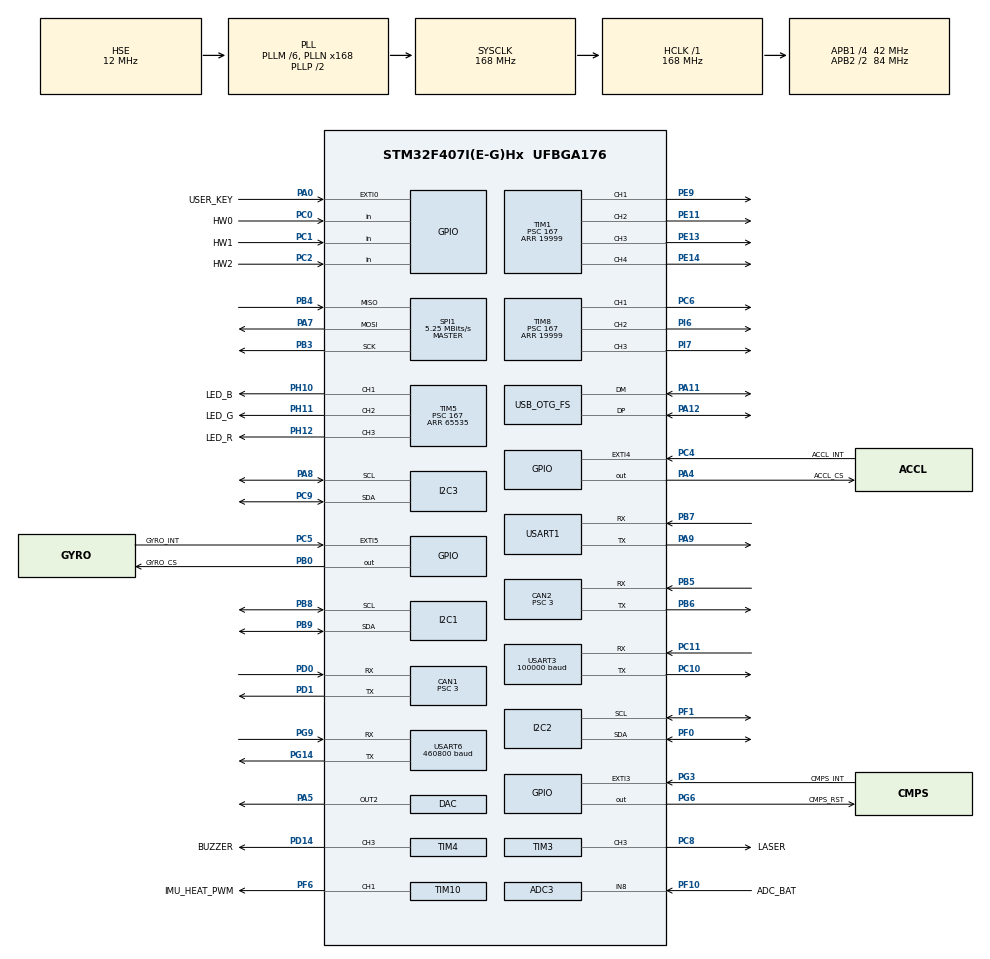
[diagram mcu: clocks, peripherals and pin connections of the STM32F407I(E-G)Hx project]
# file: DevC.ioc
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ADC1.Channel-0\#ChannelRegularConversion=ADC_CHANNEL_TEMPSENSOR
ADC1.Channel-1\#ChannelRegularConversion=ADC_CHANNEL_VREFINT
ADC1.ClockPrescaler=ADC_CLOCK_SYNC_PCLK_DIV6
ADC1.ContinuousConvMode=ENABLE
ADC1.DMAContinuousRequests=ENABLE
ADC1.NbrOfConversion=2
ADC1.NbrOfConversionFlag=1
ADC1.Rank-0\#ChannelRegularConversion=1
ADC1.Rank-1\#ChannelRegularConversion=2
ADC1.SamplingTime-0\#ChannelRegularConversion=ADC_SAMPLETIME_3CYCLES
ADC1.SamplingTime-1\#ChannelRegularConversion=ADC_SAMPLETIME_3CYCLES
ADC1.master=1
ADC3.Channel-0\#ChannelRegularConversion=ADC_CHANNEL_8
ADC3.ClockPrescaler=ADC_CLOCK_SYNC_PCLK_DIV6
ADC3.ContinuousConvMode=ENABLE
ADC3.DMAContinuousRequests=ENABLE
ADC3.NbrOfConversionFlag=1
ADC3.Rank-0\#ChannelRegularConversion=1
ADC3.SamplingTime-0\#ChannelRegularConversion=ADC_SAMPLETIME_3CYCLES
CAN1.ABOM=ENABLE
CAN1.AWUM=ENABLE
CAN1.BS1=CAN_BS1_6TQ
CAN1.BS2=CAN_BS2_7TQ
CAN1.CalculateBaudRate=1000000
CAN1.CalculateTimeBit=1000
CAN1.CalculateTimeQuantum=71.42857142857143
CAN1.Mode=CAN_MODE_NORMAL
CAN1.NART=ENABLE
CAN1.Prescaler=3
CAN1.TXFP=DISABLE
CAN2.ABOM=ENABLE
CAN2.AWUM=ENABLE
CAN2.BS1=CAN_BS1_6TQ
CAN2.BS2=CAN_BS2_7TQ
CAN2.CalculateBaudRate=1000000
CAN2.CalculateTimeBit=1000
CAN2.CalculateTimeQuantum=71.42857142857143
CAN2.Mode=CAN_MODE_NORMAL
CAN2.NART=ENABLE
CAN2.Prescaler=3
CAN2.TXFP=DISABLE
Dma.ADC1.11.Direction=DMA_PERIPH_TO_MEMORY
Dma.ADC1.11.FIFOMode=DMA_FIFOMODE_DISABLE
Dma.ADC1.11.Instance=DMA2_Stream4
Dma.ADC1.11.MemDataAlignment=DMA_MDATAALIGN_HALFWORD
Dma.ADC1.11.MemInc=DMA_MINC_ENABLE
Dma.ADC1.11.Mode=DMA_CIRCULAR
Dma.ADC1.11.PeriphDataAlignment=DMA_PDATAALIGN_HALFWORD
Dma.ADC1.11.PeriphInc=DMA_PINC_DISABLE
Dma.ADC1.11.Priority=DMA_PRIORITY_LOW
Dma.ADC3.10.Direction=DMA_PERIPH_TO_MEMORY
Dma.ADC3.10.FIFOMode=DMA_FIFOMODE_DISABLE
Dma.ADC3.10.Instance=DMA2_Stream1
Dma.ADC3.10.MemDataAlignment=DMA_MDATAALIGN_HALFWORD
Dma.ADC3.10.MemInc=DMA_MINC_ENABLE
Dma.ADC3.10.Mode=DMA_CIRCULAR
Dma.ADC3.10.PeriphDataAlignment=DMA_PDATAALIGN_HALFWORD
Dma.ADC3.10.PeriphInc=DMA_PINC_DISABLE
Dma.ADC3.10.Priority=DMA_PRIORITY_LOW
Dma.I2C2_TX.2.Direction=DMA_MEMORY_TO_PERIPH
Dma.I2C2_TX.2.FIFOMode=DMA_FIFOMODE_DISABLE
Dma.I2C2_TX.2.Instance=DMA1_Stream7
Dma.I2C2_TX.2.MemDataAlignment=DMA_MDATAALIGN_BYTE
Dma.I2C2_TX.2.MemInc=DMA_MINC_ENABLE
Dma.I2C2_TX.2.Mode=DMA_NORMAL
Dma.I2C2_TX.2.PeriphDataAlignment=DMA_PDATAALIGN_BYTE
Dma.I2C2_TX.2.PeriphInc=DMA_PINC_DISABLE
Dma.I2C2_TX.2.Priority=DMA_PRIORITY_HIGH
Dma.I2C3_RX.7.Direction=DMA_PERIPH_TO_MEMORY
Dma.I2C3_RX.7.FIFOMode=DMA_FIFOMODE_DISABLE
Dma.I2C3_RX.7.Instance=DMA1_Stream2
Dma.I2C3_RX.7.MemDataAlignment=DMA_MDATAALIGN_BYTE
Dma.I2C3_RX.7.MemInc=DMA_MINC_ENABLE
Dma.I2C3_RX.7.Mode=DMA_NORMAL
Dma.I2C3_RX.7.PeriphDataAlignment=DMA_PDATAALIGN_BYTE
Dma.I2C3_RX.7.PeriphInc=DMA_PINC_DISABLE
Dma.I2C3_RX.7.Priority=DMA_PRIORITY_LOW
Dma.I2C3_TX.9.Direction=DMA_MEMORY_TO_PERIPH
Dma.I2C3_TX.9.FIFOMode=DMA_FIFOMODE_DISABLE
Dma.I2C3_TX.9.Instance=DMA1_Stream4
Dma.I2C3_TX.9.MemDataAlignment=DMA_MDATAALIGN_BYTE
Dma.I2C3_TX.9.MemInc=DMA_MINC_ENABLE
Dma.I2C3_TX.9.Mode=DMA_NORMAL
Dma.I2C3_TX.9.PeriphDataAlignment=DMA_PDATAALIGN_BYTE
Dma.I2C3_TX.9.PeriphInc=DMA_PINC_DISABLE
Dma.I2C3_TX.9.Priority=DMA_PRIORITY_LOW
Dma.Request0=SPI1_RX
Dma.Request1=SPI1_TX
Dma.Request10=ADC3
Dma.Request11=ADC1
Dma.Request2=I2C2_TX
Dma.Request3=USART3_RX
Dma.Request4=USART6_RX
Dma.Request5=USART6_TX
Dma.Request6=USART1_TX
Dma.Request7=I2C3_RX
Dma.Request8=USART1_RX
Dma.Request9=I2C3_TX
Dma.SPI1_RX.0.Direction=DMA_PERIPH_TO_MEMORY
Dma.SPI1_RX.0.FIFOMode=DMA_FIFOMODE_DISABLE
Dma.SPI1_RX.0.Instance=DMA2_Stream0
Dma.SPI1_RX.0.MemDataAlignment=DMA_MDATAALIGN_BYTE
Dma.SPI1_RX.0.MemInc=DMA_MINC_ENABLE
Dma.SPI1_RX.0.Mode=DMA_NORMAL
Dma.SPI1_RX.0.PeriphDataAlignment=DMA_PDATAALIGN_BYTE
Dma.SPI1_RX.0.PeriphInc=DMA_PINC_DISABLE
Dma.SPI1_RX.0.Priority=DMA_PRIORITY_VERY_HIGH
Dma.SPI1_TX.1.Direction=DMA_MEMORY_TO_PERIPH
Dma.SPI1_TX.1.FIFOMode=DMA_FIFOMODE_DISABLE
Dma.SPI1_TX.1.Instance=DMA2_Stream3
Dma.SPI1_TX.1.MemDataAlignment=DMA_MDATAALIGN_BYTE
Dma.SPI1_TX.1.MemInc=DMA_MINC_ENABLE
Dma.SPI1_TX.1.Mode=DMA_NORMAL
Dma.SPI1_TX.1.PeriphDataAlignment=DMA_PDATAALIGN_BYTE
Dma.SPI1_TX.1.PeriphInc=DMA_PINC_DISABLE
Dma.SPI1_TX.1.Priority=DMA_PRIORITY_HIGH
Dma.USART1_RX.8.Direction=DMA_PERIPH_TO_MEMORY
Dma.USART1_RX.8.FIFOMode=DMA_FIFOMODE_DISABLE
Dma.USART1_RX.8.Instance=DMA2_Stream5
Dma.USART1_RX.8.MemDataAlignment=DMA_MDATAALIGN_BYTE
Dma.USART1_RX.8.MemInc=DMA_MINC_ENABLE
Dma.USART1_RX.8.Mode=DMA_NORMAL
Dma.USART1_RX.8.PeriphDataAlignment=DMA_PDATAALIGN_BYTE
Dma.USART1_RX.8.PeriphInc=DMA_PINC_DISABLE
Dma.USART1_RX.8.Priority=DMA_PRIORITY_MEDIUM
Dma.USART1_TX.6.Direction=DMA_MEMORY_TO_PERIPH
Dma.USART1_TX.6.FIFOMode=DMA_FIFOMODE_DISABLE
Dma.USART1_TX.6.Instance=DMA2_Stream7
Dma.USART1_TX.6.MemDataAlignment=DMA_MDATAALIGN_BYTE
Dma.USART1_TX.6.MemInc=DMA_MINC_ENABLE
Dma.USART1_TX.6.Mode=DMA_NORMAL
Dma.USART1_TX.6.PeriphDataAlignment=DMA_PDATAALIGN_BYTE
Dma.USART1_TX.6.PeriphInc=DMA_PINC_DISABLE
Dma.USART1_TX.6.Priority=DMA_PRIORITY_MEDIUM
Dma.USART3_RX.3.Direction=DMA_PERIPH_TO_MEMORY
Dma.USART3_RX.3.FIFOMode=DMA_FIFOMODE_DISABLE
Dma.USART3_RX.3.Instance=DMA1_Stream1
Dma.USART3_RX.3.MemDataAlignment=DMA_MDATAALIGN_BYTE
Dma.USART3_RX.3.MemInc=DMA_MINC_ENABLE
Dma.USART3_RX.3.Mode=DMA_NORMAL
Dma.USART3_RX.3.PeriphDataAlignment=DMA_PDATAALIGN_BYTE
Dma.USART3_RX.3.PeriphInc=DMA_PINC_DISABLE
Dma.USART3_RX.3.Priority=DMA_PRIORITY_HIGH
Dma.USART6_RX.4.Direction=DMA_PERIPH_TO_MEMORY
Dma.USART6_RX.4.FIFOMode=DMA_FIFOMODE_DISABLE
Dma.USART6_RX.4.Instance=DMA2_Stream2
Dma.USART6_RX.4.MemDataAlignment=DMA_MDATAALIGN_BYTE
Dma.USART6_RX.4.MemInc=DMA_MINC_ENABLE
Dma.USART6_RX.4.Mode=DMA_NORMAL
Dma.USART6_RX.4.PeriphDataAlignment=DMA_PDATAALIGN_BYTE
Dma.USART6_RX.4.PeriphInc=DMA_PINC_DISABLE
Dma.USART6_RX.4.Priority=DMA_PRIORITY_MEDIUM
Dma.USART6_TX.5.Direction=DMA_MEMORY_TO_PERIPH
Dma.USART6_TX.5.FIFOMode=DMA_FIFOMODE_DISABLE
Dma.USART6_TX.5.Instance=DMA2_Stream6
Dma.USART6_TX.5.MemDataAlignment=DMA_MDATAALIGN_BYTE
Dma.USART6_TX.5.MemInc=DMA_MINC_ENABLE
Dma.USART6_TX.5.Mode=DMA_NORMAL
Dma.USART6_TX.5.PeriphDataAlignment=DMA_PDATAALIGN_BYTE
Dma.USART6_TX.5.PeriphInc=DMA_PINC_DISABLE
Dma.USART6_TX.5.Priority=DMA_PRIORITY_MEDIUM
FREERTOS.INCLUDE_uxTaskPriorityGet=0
FREERTOS.INCLUDE_vTaskDelayUntil=1
FREERTOS.INCLUDE_vTaskDelete=0
FREERTOS.INCLUDE_vTaskPrioritySet=0
FREERTOS.INCLUDE_vTaskSuspend=0
FREERTOS.MEMORY_ALLOCATION=0
FREERTOS.Tasks01=defaultTask,0,4096,StartDefaultTask,Default,NULL,Dynamic,NULL,NULL
FREERTOS.configENABLE_BACKWARD_COMPATIBILITY=0
FREERTOS.configENABLE_FPU=1
FREERTOS.configGENERATE_RUN_TIME_STATS=1
FREERTOS.configMAX_PRIORITIES=6
FREERTOS.configTOTAL_HEAP_SIZE=1024*64
FREERTOS.configUSE_COUNTING_SEMAPHORES=1
FREERTOS.configUSE_MUTEXES=1
FREERTOS.configUSE_NEWLIB_REENTRANT=0
FREERTOS.configUSE_STATS_FORMATTING_FUNCTIONS=1
FREERTOS.configUSE_TRACE_FACILITY=1
I2C1.I2C_Mode=I2C_Fast
I2C2.I2C_Mode=I2C_Fast
I2C3.I2C_Mode=I2C_Fast
Mcu.Family=STM32F4
Mcu.Name=STM32F407I(E-G)Hx
Mcu.Package=UFBGA176
NVIC.CAN1_RX0_IRQn=true\:5\:0\:true\:false\:true\:true\:true\:true\:true
NVIC.CAN1_RX1_IRQn=true\:5\:0\:true\:false\:true\:true\:true\:true\:true
NVIC.CAN1_TX_IRQn=true\:5\:0\:true\:false\:true\:true\:true\:true\:true
NVIC.CAN2_RX0_IRQn=true\:5\:0\:true\:false\:true\:true\:true\:true\:true
NVIC.CAN2_RX1_IRQn=true\:5\:0\:true\:false\:true\:true\:true\:true\:true
NVIC.CAN2_TX_IRQn=true\:5\:0\:true\:false\:true\:true\:true\:true\:true
NVIC.DMA1_Stream1_IRQn=true\:5\:0\:true\:false\:true\:true\:false\:true\:true
NVIC.DMA1_Stream2_IRQn=true\:5\:0\:true\:false\:true\:true\:false\:true\:true
NVIC.DMA1_Stream4_IRQn=true\:5\:0\:false\:false\:true\:true\:false\:true\:true
NVIC.DMA1_Stream7_IRQn=true\:5\:0\:true\:false\:true\:true\:false\:true\:true
NVIC.DMA2_Stream0_IRQn=true\:5\:0\:true\:false\:true\:true\:false\:true\:true
NVIC.DMA2_Stream1_IRQn=true\:5\:0\:false\:false\:true\:true\:false\:true\:true
NVIC.DMA2_Stream2_IRQn=true\:5\:0\:true\:false\:true\:true\:false\:true\:true
NVIC.DMA2_Stream3_IRQn=true\:5\:0\:true\:false\:true\:true\:false\:true\:true
NVIC.DMA2_Stream4_IRQn=true\:5\:0\:false\:false\:true\:true\:false\:true\:true
NVIC.DMA2_Stream5_IRQn=true\:5\:0\:true\:false\:true\:true\:false\:true\:true
NVIC.DMA2_Stream6_IRQn=true\:5\:0\:true\:false\:true\:true\:false\:true\:true
NVIC.DMA2_Stream7_IRQn=true\:5\:0\:true\:false\:true\:true\:false\:true\:true
NVIC.EXTI0_IRQn=true\:5\:0\:true\:false\:true\:true\:true\:true\:true
NVIC.EXTI3_IRQn=true\:5\:0\:true\:false\:true\:true\:true\:true\:true
NVIC.EXTI4_IRQn=true\:5\:0\:true\:false\:true\:true\:true\:true\:true
NVIC.EXTI9_5_IRQn=true\:5\:0\:true\:false\:true\:true\:true\:true\:true
NVIC.I2C3_EV_IRQn=true\:5\:0\:false\:false\:true\:true\:true\:true\:true
NVIC.OTG_FS_IRQn=true\:5\:0\:true\:false\:true\:true\:true\:true\:true
NVIC.PriorityGroup=NVIC_PRIORITYGROUP_4
NVIC.SPI1_IRQn=true\:5\:0\:false\:false\:true\:true\:true\:true\:true
NVIC.TIM1_BRK_TIM9_IRQn=true\:5\:0\:true\:false\:true\:true\:false\:true\:true
NVIC.TIM2_IRQn=true\:15\:0\:true\:false\:true\:false\:false\:true\:true
NVIC.TIM7_IRQn=true\:5\:0\:true\:false\:true\:true\:true\:true\:true
NVIC.TimeBase=TIM2_IRQn
NVIC.TimeBaseIP=TIM2
NVIC.USART1_IRQn=true\:5\:0\:true\:false\:true\:true\:true\:true\:true
NVIC.USART3_IRQn=true\:5\:0\:false\:false\:true\:true\:true\:true\:true
NVIC.USART6_IRQn=true\:5\:0\:true\:false\:true\:true\:true\:true\:true
PA0-WKUP.GPIO_Label=USER_KEY
PA0-WKUP.GPIO_ModeDefaultEXTI=GPIO_MODE_IT_FALLING
PA0-WKUP.GPIO_PuPd=GPIO_PULLUP
PA0-WKUP.Signal=GPXTI0
PA11.Mode=Device_Only
PA11.Signal=USB_OTG_FS_DM
PA12.Mode=Device_Only
PA12.Signal=USB_OTG_FS_DP
PA13.Mode=Serial_Wire
PA13.Signal=SYS_JTMS-SWDIO
PA14.Mode=Serial_Wire
PA14.Signal=SYS_JTCK-SWCLK
PA4.GPIO_Label=ACCL_CS
PA4.GPIO_PuPd=GPIO_PULLUP
PA4.GPIO_Speed=GPIO_SPEED_FREQ_MEDIUM
PA4.PinState=GPIO_PIN_SET
PA4.Signal=GPIO_Output
PA5.Signal=COMP_DAC2_group
PA7.GPIO_PuPd=GPIO_PULLUP
PA7.Mode=Full_Duplex_Master
PA7.Signal=SPI1_MOSI
PA8.GPIO_Pu=GPIO_PULLUP
PA8.Mode=I2C
PA8.Signal=I2C3_SCL
PA9.Mode=Asynchronous
PA9.Signal=USART1_TX
PB0.GPIO_Label=GYRO_CS
PB0.GPIO_PuPd=GPIO_PULLUP
PB0.GPIO_Speed=GPIO_SPEED_FREQ_MEDIUM
PB0.PinState=GPIO_PIN_SET
PB0.Signal=GPIO_Output
PB14.GPIO_PuPd=GPIO_PULLUP
PB14.Signal=SPI2_MISO
PB15.GPIO_PuPd=GPIO_PULLUP
PB15.Signal=SPI2_MOSI
PB3.GPIO_PuPd=GPIO_PULLUP
PB3.Mode=Full_Duplex_Master
PB3.Signal=SPI1_SCK
PB4.GPIO_PuPd=GPIO_PULLUP
PB4.Mode=Full_Duplex_Master
PB4.Signal=SPI1_MISO
PB5.Mode=CAN_Activate
PB5.Signal=CAN2_RX
PB6.Mode=CAN_Activate
PB6.Signal=CAN2_TX
PB7.Mode=Asynchronous
PB7.Signal=USART1_RX
PB8.GPIO_Pu=GPIO_PULLUP
PB8.Mode=I2C
PB8.Signal=I2C1_SCL
PB9.GPIO_Pu=GPIO_PULLUP
PB9.Mode=I2C
PB9.Signal=I2C1_SDA
PC0.GPIO_Label=HW0
PC0.Signal=GPIO_Input
PC1.GPIO_Label=HW1
PC1.Signal=GPIO_Input
PC10.Mode=Asynchronous
PC10.Signal=USART3_TX
PC11.Mode=Asynchronous
PC11.Signal=USART3_RX
PC2.GPIO_Label=HW2
PC2.Signal=GPIO_Input
PC4.GPIO_Label=ACCL_INT
PC4.GPIO_ModeDefaultEXTI=GPIO_MODE_IT_FALLING
PC4.GPIO_PuPd=GPIO_PULLUP
PC4.Signal=GPXTI4
PC5.GPIO_Label=GYRO_INT
PC5.GPIO_ModeDefaultEXTI=GPIO_MODE_IT_FALLING
PC5.GPIO_PuPd=GPIO_PULLUP
PC5.Signal=GPXTI5
PC6.GPIO_PuPd=GPIO_PULLUP
PC6.GPIO_Speed=GPIO_SPEED_FREQ_HIGH
PC6.Signal=S_TIM8_CH1
PC8.GPIO_Label=LASER
PC8.GPIO_PuPd=GPIO_PULLUP
PC8.GPIO_Speed=GPIO_SPEED_FREQ_HIGH
PC8.Signal=S_TIM3_CH3
PC9.GPIO_Pu=GPIO_PULLUP
PC9.Mode=I2C
PC9.Signal=I2C3_SDA
PD0.Mode=CAN_Activate
PD0.Signal=CAN1_RX
PD1.Mode=CAN_Activate
PD1.Signal=CAN1_TX
PD14.GPIO_Label=BUZZER
PD14.GPIO_PuPd=GPIO_PULLUP
PD14.GPIO_Speed=GPIO_SPEED_FREQ_VERY_HIGH
PD14.Signal=S_TIM4_CH3
PE11.GPIO_PuPd=GPIO_PULLUP
PE11.GPIO_Speed=GPIO_SPEED_FREQ_HIGH
PE11.Signal=S_TIM1_CH2
PE13.GPIO_PuPd=GPIO_PULLUP
PE13.GPIO_Speed=GPIO_SPEED_FREQ_HIGH
PE13.Signal=S_TIM1_CH3
PE14.GPIO_PuPd=GPIO_PULLUP
PE14.GPIO_Speed=GPIO_SPEED_FREQ_HIGH
PE14.Signal=S_TIM1_CH4
PE9.GPIO_PuPd=GPIO_PULLUP
PE9.GPIO_Speed=GPIO_SPEED_FREQ_HIGH
PE9.Signal=S_TIM1_CH1
PF0.GPIO_Pu=GPIO_PULLUP
PF0.Mode=I2C
PF0.Signal=I2C2_SDA
PF1.GPIO_Pu=GPIO_PULLUP
PF1.Mode=I2C
PF1.Signal=I2C2_SCL
PF10.GPIO_Label=ADC_BAT
PF10.Mode=IN8
PF10.Signal=ADC3_IN8
PF6.GPIO_Label=IMU_HEAT_PWM
PF6.GPIO_PuPd=GPIO_PULLDOWN
PF6.GPIO_Speed=GPIO_SPEED_FREQ_HIGH
PF6.Signal=S_TIM10_CH1
PG14.Mode=Asynchronous
PG14.Signal=USART6_TX
PG3.GPIO_Label=CMPS_INT
PG3.GPIO_ModeDefaultEXTI=GPIO_MODE_IT_FALLING
PG3.GPIO_PuPd=GPIO_PULLUP
PG3.Signal=GPXTI3
PG6.GPIO_Label=CMPS_RST
PG6.GPIO_PuPd=GPIO_PULLUP
PG6.GPIO_Speed=GPIO_SPEED_FREQ_MEDIUM
PG6.PinState=GPIO_PIN_RESET
PG6.Signal=GPIO_Output
PG9.Mode=Asynchronous
PG9.Signal=USART6_RX
PH0-OSC_IN.Mode=HSE-External-Oscillator
PH0-OSC_IN.Signal=RCC_OSC_IN
PH1-OSC_OUT.Mode=HSE-External-Oscillator
PH1-OSC_OUT.Signal=RCC_OSC_OUT
PH10.GPIO_Label=LED_B
PH10.GPIO_PuPd=GPIO_PULLUP
PH10.GPIO_Speed=GPIO_SPEED_FREQ_HIGH
PH10.Signal=S_TIM5_CH1
PH11.GPIO_Label=LED_G
PH11.GPIO_PuPd=GPIO_PULLUP
PH11.GPIO_Speed=GPIO_SPEED_FREQ_HIGH
PH11.Signal=S_TIM5_CH2
PH12.GPIO_Label=LED_R
PH12.GPIO_PuPd=GPIO_PULLUP
PH12.GPIO_Speed=GPIO_SPEED_FREQ_HIGH
PH12.Signal=S_TIM5_CH3
PI6.GPIO_PuPd=GPIO_PULLUP
PI6.GPIO_Speed=GPIO_SPEED_FREQ_HIGH
PI6.Signal=S_TIM8_CH2
PI7.Signal=S_TIM8_CH3
ProjectManager.HeapSize=0x1000
ProjectManager.StackSize=0x1000
ProjectManager.TargetToolchain=CMake
RCC.48MHZClocksFreq_Value=48000000
RCC.AHBFreq_Value=168000000
RCC.APB1CLKDivider=RCC_HCLK_DIV4
RCC.APB1Freq_Value=42000000
RCC.APB1TimFreq_Value=84000000
RCC.APB2CLKDivider=RCC_HCLK_DIV2
RCC.APB2Freq_Value=84000000
RCC.APB2TimFreq_Value=168000000
RCC.CortexFreq_Value=168000000
RCC.HCLKFreq_Value=168000000
RCC.HSE_VALUE=12000000
RCC.HSI_VALUE=16000000
RCC.LSE_VALUE=32768
RCC.PLLM=6
RCC.PLLN=168
RCC.PLLQ=7
RCC.RCC_RTC_Clock_Source=RCC_RTCCLKSOURCE_LSI
RCC.RCC_RTC_Clock_SourceVirtual=RCC_RTCCLKSOURCE_HSE_DIV30
RCC.RCC_RTC_Clock_Source_FROM_HSE=RCC_RTCCLKSOURCE_HSE_DIV30
RCC.SYSCLKFreq_VALUE=168000000
RCC.SYSCLKSource=RCC_SYSCLKSOURCE_PLLCLK
RCC.VCOOutputFreq_Value=336000000
SH.COMP_DAC2_group.0=DAC_OUT2,DAC_OUT2
SH.S_TIM10_CH1.0=TIM10_CH1,PWM Generation1 CH1
SH.S_TIM1_CH1.0=TIM1_CH1,PWM Generation1 CH1
SH.S_TIM1_CH2.0=TIM1_CH2,PWM Generation2 CH2
SH.S_TIM1_CH3.0=TIM1_CH3,PWM Generation3 CH3
SH.S_TIM1_CH4.0=TIM1_CH4,PWM Generation4 CH4
SH.S_TIM3_CH3.0=TIM3_CH3,PWM Generation3 CH3
SH.S_TIM4_CH3.0=TIM4_CH3,PWM Generation3 CH3
SH.S_TIM5_CH1.0=TIM5_CH1,PWM Generation1 CH1
SH.S_TIM5_CH2.0=TIM5_CH2,PWM Generation2 CH2
SH.S_TIM5_CH3.0=TIM5_CH3,PWM Generation3 CH3
SH.S_TIM8_CH1.0=TIM8_CH1,PWM Generation1 CH1
SH.S_TIM8_CH2.0=TIM8_CH2,PWM Generation2 CH2
SH.S_TIM8_CH3.0=TIM8_CH3,PWM Generation3 CH3
SPI1.BaudRatePrescaler=SPI_BAUDRATEPRESCALER_16
SPI1.CLKPhase=SPI_PHASE_2EDGE
SPI1.CLKPolarity=SPI_POLARITY_HIGH
SPI1.CalculateBaudRate=5.25 MBits/s
SPI1.Direction=SPI_DIRECTION_2LINES
SPI1.Mode=SPI_MODE_MASTER
SPI1.VirtualType=VM_MASTER
TIM1.Channel-PWM\ Generation1\ CH1=TIM_CHANNEL_1
TIM1.Channel-PWM\ Generation2\ CH2=TIM_CHANNEL_2
TIM1.Channel-PWM\ Generation3\ CH3=TIM_CHANNEL_3
TIM1.Channel-PWM\ Generation4\ CH4=TIM_CHANNEL_4
TIM1.Period=19999
TIM1.Prescaler=167
TIM1.Pulse-PWM\ Generation1\ CH1=0
TIM1.Pulse-PWM\ Generation2\ CH2=0
TIM1.Pulse-PWM\ Generation3\ CH3=0
TIM1.Pulse-PWM\ Generation4\ CH4=1000
TIM10.Channel=TIM_CHANNEL_1
TIM10.Period=4999
TIM10.Prescaler=167
TIM3.Channel-PWM\ Generation3\ CH3=TIM_CHANNEL_3
TIM3.Period=65535
TIM3.Prescaler=167
TIM4.Channel-PWM\ Generation3\ CH3=TIM_CHANNEL_3
TIM4.Period=65535
TIM4.Prescaler=167
TIM5.Channel-PWM\ Generation1\ CH1=TIM_CHANNEL_1
TIM5.Channel-PWM\ Generation2\ CH2=TIM_CHANNEL_2
TIM5.Channel-PWM\ Generation3\ CH3=TIM_CHANNEL_3
TIM5.Period=65535
TIM5.Prescaler=167
TIM7.Period=9
TIM7.Prescaler=167
TIM8.Channel-PWM\ Generation1\ CH1=TIM_CHANNEL_1
TIM8.Channel-PWM\ Generation2\ CH2=TIM_CHANNEL_2
TIM8.Channel-PWM\ Generation3\ CH3=TIM_CHANNEL_3
TIM8.Period=19999
TIM8.Prescaler=167
TIM8.Pulse-PWM\ Generation1\ CH1=1000
TIM8.Pulse-PWM\ Generation2\ CH2=1000
USART1.VirtualMode=VM_ASYNC
USART3.BaudRate=100000
USART3.Mode=MODE_RX
USART3.Parity=PARITY_EVEN
USART3.VirtualMode=VM_ASYNC
USART3.WordLength=WORDLENGTH_9B
USART6.BaudRate=460800
USART6.VirtualMode=VM_ASYNC
USB_OTG_FS.VirtualMode=Device_Only
VP_ADC1_TempSens_Input.Mode=IN-TempSens
VP_ADC1_Vref_Input.Mode=IN-Vrefint
VP_FREERTOS_VS_CMSIS_V1.Mode=CMSIS_V1
VP_IWDG_VS_IWDG.Mode=IWDG_Activate
VP_RNG_VS_RNG.Mode=RNG_Activate
VP_SYS_VS_tim2.Mode=TIM2
VP_TIM10_VS_ClockSourceINT.Mode=Enable_Timer
VP_TIM1_VS_ClockSourceINT.Mode=Internal
VP_TIM3_VS_ClockSourceINT.Mode=Internal
VP_TIM4_VS_ClockSourceINT.Mode=Internal
VP_TIM5_VS_ClockSourceINT.Mode=Internal
VP_TIM7_VS_ClockSourceINT.Mode=Enable_Timer
VP_TIM8_VS_ClockSourceINT.Mode=Internal
board=custom

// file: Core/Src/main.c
/* USER CODE BEGIN Header */
/**
  ******************************************************************************
  * @file           : main.c
  * @brief          : Main program body
  ******************************************************************************
  * @attention
  *
  * Copyright (c) 2025 STMicroelectronics.
  * All rights reserved.
  *
  * This software is licensed under terms that can be found in the LICENSE file
  * in the root directory of this software component.
  * If no LICENSE file comes with this software, it is provided AS-IS.
  *
  ******************************************************************************
  */
/* USER CODE END Header */
#include "main.h"
#include "cmsis_os.h"

ADC_HandleTypeDef hadc1;
ADC_HandleTypeDef hadc3;
DMA_HandleTypeDef hdma_adc1;
DMA_HandleTypeDef hdma_adc3;

CAN_HandleTypeDef hcan1;
CAN_HandleTypeDef hcan2;

DAC_HandleTypeDef hdac;

I2C_HandleTypeDef hi2c1;
I2C_HandleTypeDef hi2c2;
I2C_HandleTypeDef hi2c3;
DMA_HandleTypeDef hdma_i2c2_tx;
DMA_HandleTypeDef hdma_i2c3_rx;
DMA_HandleTypeDef hdma_i2c3_tx;

IWDG_HandleTypeDef hiwdg;

RNG_HandleTypeDef hrng;

SPI_HandleTypeDef hspi1;
DMA_HandleTypeDef hdma_spi1_rx;
DMA_HandleTypeDef hdma_spi1_tx;

TIM_HandleTypeDef htim1;
TIM_HandleTypeDef htim3;
TIM_HandleTypeDef htim4;
TIM_HandleTypeDef htim5;
TIM_HandleTypeDef htim7;
TIM_HandleTypeDef htim8;
TIM_HandleTypeDef htim10;

UART_HandleTypeDef huart1;
UART_HandleTypeDef huart3;
UART_HandleTypeDef huart6;
DMA_HandleTypeDef hdma_usart1_tx;
DMA_HandleTypeDef hdma_usart1_rx;
DMA_HandleTypeDef hdma_usart3_rx;
DMA_HandleTypeDef hdma_usart6_rx;
DMA_HandleTypeDef hdma_usart6_tx;

PCD_HandleTypeDef hpcd_USB_OTG_FS;

osThreadId defaultTaskHandle;

void SystemClock_Config(void);
static void MX_IWDG_Init(void);
static void MX_DAC_Init(void);
static void MX_USB_OTG_FS_PCD_Init(void);
void StartDefaultTask(void const * argument);

int main(void)
{

  /* MCU Configuration--------------------------------------------------------*/

  /* Reset of all peripherals, Initializes the Flash interface and the Systick. */
  HAL_Init();

  /* Configure the system clock */
  SystemClock_Config();

  /* Initialize all configured peripherals */
  MX_GPIO_Init();
  MX_DMA_Init();
  MX_ADC1_Init();
  MX_ADC3_Init();
  MX_CAN1_Init();
  MX_CAN2_Init();
  MX_I2C1_Init();
  MX_SPI1_Init();
  MX_TIM4_Init();
  MX_TIM5_Init();
  MX_USART3_UART_Init();
  MX_TIM8_Init();
  MX_RNG_Init();
  MX_I2C2_Init();
  MX_I2C3_Init();
  MX_TIM1_Init();
  MX_TIM3_Init();
  MX_TIM10_Init();
  MX_USART1_UART_Init();
  MX_USART6_UART_Init();
  MX_TIM7_Init();
  MX_IWDG_Init();
  MX_DAC_Init();
  MX_USB_OTG_FS_PCD_Init();

  /* Create the thread(s) */
  /* definition and creation of defaultTask */
  osThreadDef(defaultTask, StartDefaultTask, osPriorityNormal, 0, 4096);
  defaultTaskHandle = osThreadCreate(osThread(defaultTask), NULL);

  /* Start scheduler */
  osKernelStart();

  /* We should never get here as control is now taken by the scheduler */

  /* Infinite loop */
  while (1)
  {

  }
}

void SystemClock_Config(void)
{
  RCC_OscInitTypeDef RCC_OscInitStruct = {0};
  RCC_ClkInitTypeDef RCC_ClkInitStruct = {0};

  /** Configure the main internal regulator output voltage
  */
  __HAL_RCC_PWR_CLK_ENABLE();
  __HAL_PWR_VOLTAGESCALING_CONFIG(PWR_REGULATOR_VOLTAGE_SCALE1);

  /** Initializes the RCC Oscillators according to the specified parameters
  * in the RCC_OscInitTypeDef structure.
  */
  RCC_OscInitStruct.OscillatorType = RCC_OSCILLATORTYPE_LSI|RCC_OSCILLATORTYPE_HSE;
  RCC_OscInitStruct.HSEState = RCC_HSE_ON;
  RCC_OscInitStruct.LSIState = RCC_LSI_ON;
  RCC_OscInitStruct.PLL.PLLState = RCC_PLL_ON;
  RCC_OscInitStruct.PLL.PLLSource = RCC_PLLSOURCE_HSE;
  RCC_OscInitStruct.PLL.PLLM = 6;
  RCC_OscInitStruct.PLL.PLLN = 168;
  RCC_OscInitStruct.PLL.PLLP = RCC_PLLP_DIV2;
  RCC_OscInitStruct.PLL.PLLQ = 7;
  if (HAL_RCC_OscConfig(&RCC_OscInitStruct) != HAL_OK)
  {
    Error_Handler();
  }

  /** Initializes the CPU, AHB and APB buses clocks
  */
  RCC_ClkInitStruct.ClockType = RCC_CLOCKTYPE_HCLK|RCC_CLOCKTYPE_SYSCLK
                              |RCC_CLOCKTYPE_PCLK1|RCC_CLOCKTYPE_PCLK2;
  RCC_ClkInitStruct.SYSCLKSource = RCC_SYSCLKSOURCE_PLLCLK;
  RCC_ClkInitStruct.AHBCLKDivider = RCC_SYSCLK_DIV1;
  RCC_ClkInitStruct.APB1CLKDivider = RCC_HCLK_DIV4;
  RCC_ClkInitStruct.APB2CLKDivider = RCC_HCLK_DIV2;

  if (HAL_RCC_ClockConfig(&RCC_ClkInitStruct, FLASH_LATENCY_5) != HAL_OK)
  {
    Error_Handler();
  }
}

void MX_ADC1_Init(void)
{

  ADC_ChannelConfTypeDef sConfig = {0};

  /** Configure the global features of the ADC (Clock, Resolution, Data Alignment and number of conversion)
  */
  hadc1.Instance = ADC1;
  hadc1.Init.ClockPrescaler = ADC_CLOCK_SYNC_PCLK_DIV6;
  hadc1.Init.Resolution = ADC_RESOLUTION_12B;
  hadc1.Init.ScanConvMode = ENABLE;
  hadc1.Init.ContinuousConvMode = ENABLE;
  hadc1.Init.DiscontinuousConvMode = DISABLE;
  hadc1.Init.ExternalTrigConvEdge = ADC_EXTERNALTRIGCONVEDGE_NONE;
  hadc1.Init.ExternalTrigConv = ADC_SOFTWARE_START;
  hadc1.Init.DataAlign = ADC_DATAALIGN_RIGHT;
  hadc1.Init.NbrOfConversion = 2;
  hadc1.Init.DMAContinuousRequests = ENABLE;
  hadc1.Init.EOCSelection = ADC_EOC_SINGLE_CONV;
  if (HAL_ADC_Init(&hadc1) != HAL_OK)
  {
    Error_Handler();
  }

  /** Configure for the selected ADC regular channel its corresponding rank in the sequencer and its sample time.
  */
  sConfig.Channel = ADC_CHANNEL_TEMPSENSOR;
  sConfig.Rank = 1;
  sConfig.SamplingTime = ADC_SAMPLETIME_3CYCLES;
  if (HAL_ADC_ConfigChannel(&hadc1, &sConfig) != HAL_OK)
  {
    Error_Handler();
  }

  /** Configure for the selected ADC regular channel its corresponding rank in the sequencer and its sample time.
  */
  sConfig.Channel = ADC_CHANNEL_VREFINT;
  sConfig.Rank = 2;
  if (HAL_ADC_ConfigChannel(&hadc1, &sConfig) != HAL_OK)
  {
    Error_Handler();
  }

}

void MX_ADC3_Init(void)
{

  ADC_ChannelConfTypeDef sConfig = {0};

  /** Configure the global features of the ADC (Clock, Resolution, Data Alignment and number of conversion)
  */
  hadc3.Instance = ADC3;
  hadc3.Init.ClockPrescaler = ADC_CLOCK_SYNC_PCLK_DIV6;
  hadc3.Init.Resolution = ADC_RESOLUTION_12B;
  hadc3.Init.ScanConvMode = DISABLE;
  hadc3.Init.ContinuousConvMode = ENABLE;
  hadc3.Init.DiscontinuousConvMode = DISABLE;
  hadc3.Init.ExternalTrigConvEdge = ADC_EXTERNALTRIGCONVEDGE_NONE;
  hadc3.Init.ExternalTrigConv = ADC_SOFTWARE_START;
  hadc3.Init.DataAlign = ADC_DATAALIGN_RIGHT;
  hadc3.Init.NbrOfConversion = 1;
  hadc3.Init.DMAContinuousRequests = ENABLE;
  hadc3.Init.EOCSelection = ADC_EOC_SINGLE_CONV;
  if (HAL_ADC_Init(&hadc3) != HAL_OK)
  {
    Error_Handler();
  }

  /** Configure for the selected ADC regular channel its corresponding rank in the sequencer and its sample time.
  */
  sConfig.Channel = ADC_CHANNEL_8;
  sConfig.Rank = 1;
  sConfig.SamplingTime = ADC_SAMPLETIME_3CYCLES;
  if (HAL_ADC_ConfigChannel(&hadc3, &sConfig) != HAL_OK)
  {
    Error_Handler();
  }

}

void MX_CAN1_Init(void)
{

  hcan1.Instance = CAN1;
  hcan1.Init.Prescaler = 3;
  hcan1.Init.Mode = CAN_MODE_NORMAL;
  hcan1.Init.SyncJumpWidth = CAN_SJW_1TQ;
  hcan1.Init.TimeSeg1 = CAN_BS1_6TQ;
  hcan1.Init.TimeSeg2 = CAN_BS2_7TQ;
  hcan1.Init.TimeTriggeredMode = DISABLE;
  hcan1.Init.AutoBusOff = ENABLE;
  hcan1.Init.AutoWakeUp = ENABLE;
  hcan1.Init.AutoRetransmission = ENABLE;
  hcan1.Init.ReceiveFifoLocked = DISABLE;
  hcan1.Init.TransmitFifoPriority = DISABLE;
  if (HAL_CAN_Init(&hcan1) != HAL_OK)
  {
    Error_Handler();
  }

}

void MX_CAN2_Init(void)
{

  hcan2.Instance = CAN2;
  hcan2.Init.Prescaler = 3;
  hcan2.Init.Mode = CAN_MODE_NORMAL;
  hcan2.Init.SyncJumpWidth = CAN_SJW_1TQ;
  hcan2.Init.TimeSeg1 = CAN_BS1_6TQ;
  hcan2.Init.TimeSeg2 = CAN_BS2_7TQ;
  hcan2.Init.TimeTriggeredMode = DISABLE;
  hcan2.Init.AutoBusOff = ENABLE;
  hcan2.Init.AutoWakeUp = ENABLE;
  hcan2.Init.AutoRetransmission = ENABLE;
  hcan2.Init.ReceiveFifoLocked = DISABLE;
  hcan2.Init.TransmitFifoPriority = DISABLE;
  if (HAL_CAN_Init(&hcan2) != HAL_OK)
  {
    Error_Handler();
  }

}

static void MX_DAC_Init(void)
{

  DAC_ChannelConfTypeDef sConfig = {0};

  /** DAC Initialization
  */
  hdac.Instance = DAC;
  if (HAL_DAC_Init(&hdac) != HAL_OK)
  {
    Error_Handler();
  }

  /** DAC channel OUT2 config
  */
  sConfig.DAC_Trigger = DAC_TRIGGER_NONE;
  sConfig.DAC_OutputBuffer = DAC_OUTPUTBUFFER_ENABLE;
  if (HAL_DAC_ConfigChannel(&hdac, &sConfig, DAC_CHANNEL_2) != HAL_OK)
  {
    Error_Handler();
  }

}

void MX_I2C1_Init(void)
{

  hi2c1.Instance = I2C1;
  hi2c1.Init.ClockSpeed = 400000;
  hi2c1.Init.DutyCycle = I2C_DUTYCYCLE_2;
  hi2c1.Init.OwnAddress1 = 0;
  hi2c1.Init.AddressingMode = I2C_ADDRESSINGMODE_7BIT;
  hi2c1.Init.DualAddressMode = I2C_DUALADDRESS_DISABLE;
  hi2c1.Init.OwnAddress2 = 0;
  hi2c1.Init.GeneralCallMode = I2C_GENERALCALL_DISABLE;
  hi2c1.Init.NoStretchMode = I2C_NOSTRETCH_DISABLE;
  if (HAL_I2C_Init(&hi2c1) != HAL_OK)
  {
    Error_Handler();
  }

}

void MX_I2C2_Init(void)
{

  hi2c2.Instance = I2C2;
  hi2c2.Init.ClockSpeed = 400000;
  hi2c2.Init.DutyCycle = I2C_DUTYCYCLE_2;
  hi2c2.Init.OwnAddress1 = 0;
  hi2c2.Init.AddressingMode = I2C_ADDRESSINGMODE_7BIT;
  hi2c2.Init.DualAddressMode = I2C_DUALADDRESS_DISABLE;
  hi2c2.Init.OwnAddress2 = 0;
  hi2c2.Init.GeneralCallMode = I2C_GENERALCALL_DISABLE;
  hi2c2.Init.NoStretchMode = I2C_NOSTRETCH_DISABLE;
  if (HAL_I2C_Init(&hi2c2) != HAL_OK)
  {
    Error_Handler();
  }

}

void MX_I2C3_Init(void)
{

  hi2c3.Instance = I2C3;
  hi2c3.Init.ClockSpeed = 400000;
  hi2c3.Init.DutyCycle = I2C_DUTYCYCLE_2;
  hi2c3.Init.OwnAddress1 = 0;
  hi2c3.Init.AddressingMode = I2C_ADDRESSINGMODE_7BIT;
  hi2c3.Init.DualAddressMode = I2C_DUALADDRESS_DISABLE;
  hi2c3.Init.OwnAddress2 = 0;
  hi2c3.Init.GeneralCallMode = I2C_GENERALCALL_DISABLE;
  hi2c3.Init.NoStretchMode = I2C_NOSTRETCH_DISABLE;
  if (HAL_I2C_Init(&hi2c3) != HAL_OK)
  {
    Error_Handler();
  }

}

static void MX_IWDG_Init(void)
{

  hiwdg.Instance = IWDG;
  hiwdg.Init.Prescaler = IWDG_PRESCALER_4;
  hiwdg.Init.Reload = 4095;
  if (HAL_IWDG_Init(&hiwdg) != HAL_OK)
  {
    Error_Handler();
  }

}

void MX_RNG_Init(void)
{

  hrng.Instance = RNG;
  if (HAL_RNG_Init(&hrng) != HAL_OK)
  {
    Error_Handler();
  }

}

void MX_SPI1_Init(void)
{

  /* SPI1 parameter configuration*/
  hspi1.Instance = SPI1;
  hspi1.Init.Mode = SPI_MODE_MASTER;
  hspi1.Init.Direction = SPI_DIRECTION_2LINES;
  hspi1.Init.DataSize = SPI_DATASIZE_8BIT;
  hspi1.Init.CLKPolarity = SPI_POLARITY_HIGH;
  hspi1.Init.CLKPhase = SPI_PHASE_2EDGE;
  hspi1.Init.NSS = SPI_NSS_SOFT;
  hspi1.Init.BaudRatePrescaler = SPI_BAUDRATEPRESCALER_16;
  hspi1.Init.FirstBit = SPI_FIRSTBIT_MSB;
  hspi1.Init.TIMode = SPI_TIMODE_DISABLE;
  hspi1.Init.CRCCalculation = SPI_CRCCALCULATION_DISABLE;
  hspi1.Init.CRCPolynomial = 10;
  if (HAL_SPI_Init(&hspi1) != HAL_OK)
  {
    Error_Handler();
  }

}

void MX_TIM1_Init(void)
{

  TIM_ClockConfigTypeDef sClockSourceConfig = {0};
  TIM_MasterConfigTypeDef sMasterConfig = {0};
  TIM_OC_InitTypeDef sConfigOC = {0};
  TIM_BreakDeadTimeConfigTypeDef sBreakDeadTimeConfig = {0};

  htim1.Instance = TIM1;
  htim1.Init.Prescaler = 167;
  htim1.Init.CounterMode = TIM_COUNTERMODE_UP;
  htim1.Init.Period = 19999;
  htim1.Init.ClockDivision = TIM_CLOCKDIVISION_DIV1;
  htim1.Init.RepetitionCounter = 0;
  htim1.Init.AutoReloadPreload = TIM_AUTORELOAD_PRELOAD_DISABLE;
  if (HAL_TIM_Base_Init(&htim1) != HAL_OK)
  {
    Error_Handler();
  }
  sClockSourceConfig.ClockSource = TIM_CLOCKSOURCE_INTERNAL;
  if (HAL_TIM_ConfigClockSource(&htim1, &sClockSourceConfig) != HAL_OK)
  {
    Error_Handler();
  }
  if (HAL_TIM_PWM_Init(&htim1) != HAL_OK)
  {
    Error_Handler();
  }
  sMasterConfig.MasterOutputTrigger = TIM_TRGO_RESET;
  sMasterConfig.MasterSlaveMode = TIM_MASTERSLAVEMODE_DISABLE;
  if (HAL_TIMEx_MasterConfigSynchronization(&htim1, &sMasterConfig) != HAL_OK)
  {
    Error_Handler();
  }
  sConfigOC.OCMode = TIM_OCMODE_PWM1;
  sConfigOC.Pulse = 0;
  sConfigOC.OCPolarity = TIM_OCPOLARITY_HIGH;
  sConfigOC.OCNPolarity = TIM_OCNPOLARITY_HIGH;
  sConfigOC.OCFastMode = TIM_OCFAST_DISABLE;
  sConfigOC.OCIdleState = TIM_OCIDLESTATE_RESET;
  sConfigOC.OCNIdleState = TIM_OCNIDLESTATE_RESET;
  if (HAL_TIM_PWM_ConfigChannel(&htim1, &sConfigOC, TIM_CHANNEL_1) != HAL_OK)
  {
    Error_Handler();
  }
  if (HAL_TIM_PWM_ConfigChannel(&htim1, &sConfigOC, TIM_CHANNEL_2) != HAL_OK)
  {
    Error_Handler();
  }
  if (HAL_TIM_PWM_ConfigChannel(&htim1, &sConfigOC, TIM_CHANNEL_3) != HAL_OK)
  {
    Error_Handler();
  }
  sConfigOC.Pulse = 1000;
  if (HAL_TIM_PWM_ConfigChannel(&htim1, &sConfigOC, TIM_CHANNEL_4) != HAL_OK)
  {
    Error_Handler();
  }
  sBreakDeadTimeConfig.OffStateRunMode = TIM_OSSR_DISABLE;
  sBreakDeadTimeConfig.OffStateIDLEMode = TIM_OSSI_DISABLE;
  sBreakDeadTimeConfig.LockLevel = TIM_LOCKLEVEL_OFF;
  sBreakDeadTimeConfig.DeadTime = 0;
  sBreakDeadTimeConfig.BreakState = TIM_BREAK_DISABLE;
  sBreakDeadTimeConfig.BreakPolarity = TIM_BREAKPOLARITY_HIGH;
  sBreakDeadTimeConfig.AutomaticOutput = TIM_AUTOMATICOUTPUT_DISABLE;
  if (HAL_TIMEx_ConfigBreakDeadTime(&htim1, &sBreakDeadTimeConfig) != HAL_OK)
  {
    Error_Handler();
  }
  HAL_TIM_MspPostInit(&htim1);

}

void MX_TIM3_Init(void)
{

  TIM_ClockConfigTypeDef sClockSourceConfig = {0};
  TIM_MasterConfigTypeDef sMasterConfig = {0};
  TIM_OC_InitTypeDef sConfigOC = {0};

  htim3.Instance = TIM3;
  htim3.Init.Prescaler = 167;
  htim3.Init.CounterMode = TIM_COUNTERMODE_UP;
  htim3.Init.Period = 65535;
  htim3.Init.ClockDivision = TIM_CLOCKDIVISION_DIV1;
  htim3.Init.AutoReloadPreload = TIM_AUTORELOAD_PRELOAD_DISABLE;
  if (HAL_TIM_Base_Init(&htim3) != HAL_OK)
  {
    Error_Handler();
  }
  sClockSourceConfig.ClockSource = TIM_CLOCKSOURCE_INTERNAL;
  if (HAL_TIM_ConfigClockSource(&htim3, &sClockSourceConfig) != HAL_OK)
  {
    Error_Handler();
  }
  if (HAL_TIM_PWM_Init(&htim3) != HAL_OK)
  {
    Error_Handler();
  }
  sMasterConfig.MasterOutputTrigger = TIM_TRGO_RESET;
  sMasterConfig.MasterSlaveMode = TIM_MASTERSLAVEMODE_DISABLE;
  if (HAL_TIMEx_MasterConfigSynchronization(&htim3, &sMasterConfig) != HAL_OK)
  {
    Error_Handler();
  }
  sConfigOC.OCMode = TIM_OCMODE_PWM1;
  sConfigOC.Pulse = 0;
  sConfigOC.OCPolarity = TIM_OCPOLARITY_HIGH;
  sConfigOC.OCFastMode = TIM_OCFAST_DISABLE;
  if (HAL_TIM_PWM_ConfigChannel(&htim3, &sConfigOC, TIM_CHANNEL_3) != HAL_OK)
  {
    Error_Handler();
  }
  HAL_TIM_MspPostInit(&htim3);

}

void MX_TIM4_Init(void)
{

  TIM_ClockConfigTypeDef sClockSourceConfig = {0};
  TIM_MasterConfigTypeDef sMasterConfig = {0};
  TIM_OC_InitTypeDef sConfigOC = {0};

  htim4.Instance = TIM4;
  htim4.Init.Prescaler = 167;
  htim4.Init.CounterMode = TIM_COUNTERMODE_UP;
  htim4.Init.Period = 65535;
  htim4.Init.ClockDivision = TIM_CLOCKDIVISION_DIV1;
  htim4.Init.AutoReloadPreload = TIM_AUTORELOAD_PRELOAD_DISABLE;
  if (HAL_TIM_Base_Init(&htim4) != HAL_OK)
  {
    Error_Handler();
  }
  sClockSourceConfig.ClockSource = TIM_CLOCKSOURCE_INTERNAL;
  if (HAL_TIM_ConfigClockSource(&htim4, &sClockSourceConfig) != HAL_OK)
  {
    Error_Handler();
  }
  if (HAL_TIM_PWM_Init(&htim4) != HAL_OK)
  {
    Error_Handler();
  }
  sMasterConfig.MasterOutputTrigger = TIM_TRGO_RESET;
  sMasterConfig.MasterSlaveMode = TIM_MASTERSLAVEMODE_DISABLE;
  if (HAL_TIMEx_MasterConfigSynchronization(&htim4, &sMasterConfig) != HAL_OK)
  {
    Error_Handler();
  }
  sConfigOC.OCMode = TIM_OCMODE_PWM1;
  sConfigOC.Pulse = 0;
  sConfigOC.OCPolarity = TIM_OCPOLARITY_HIGH;
  sConfigOC.OCFastMode = TIM_OCFAST_DISABLE;
  if (HAL_TIM_PWM_ConfigChannel(&htim4, &sConfigOC, TIM_CHANNEL_3) != HAL_OK)
  {
    Error_Handler();
  }
  HAL_TIM_MspPostInit(&htim4);

}

void MX_TIM5_Init(void)
{

  TIM_ClockConfigTypeDef sClockSourceConfig = {0};
  TIM_MasterConfigTypeDef sMasterConfig = {0};
  TIM_OC_InitTypeDef sConfigOC = {0};

  htim5.Instance = TIM5;
  htim5.Init.Prescaler = 167;
  htim5.Init.CounterMode = TIM_COUNTERMODE_UP;
  htim5.Init.Period = 65535;
  htim5.Init.ClockDivision = TIM_CLOCKDIVISION_DIV1;
  htim5.Init.AutoReloadPreload = TIM_AUTORELOAD_PRELOAD_DISABLE;
  if (HAL_TIM_Base_Init(&htim5) != HAL_OK)
  {
    Error_Handler();
  }
  sClockSourceConfig.ClockSource = TIM_CLOCKSOURCE_INTERNAL;
  if (HAL_TIM_ConfigClockSource(&htim5, &sClockSourceConfig) != HAL_OK)
  {
    Error_Handler();
  }
  if (HAL_TIM_PWM_Init(&htim5) != HAL_OK)
  {
    Error_Handler();
  }
  sMasterConfig.MasterOutputTrigger = TIM_TRGO_RESET;
  sMasterConfig.MasterSlaveMode = TIM_MASTERSLAVEMODE_DISABLE;
  if (HAL_TIMEx_MasterConfigSynchronization(&htim5, &sMasterConfig) != HAL_OK)
  {
    Error_Handler();
  }
  sConfigOC.OCMode = TIM_OCMODE_PWM1;
  sConfigOC.Pulse = 0;
  sConfigOC.OCPolarity = TIM_OCPOLARITY_HIGH;
  sConfigOC.OCFastMode = TIM_OCFAST_DISABLE;
  if (HAL_TIM_PWM_ConfigChannel(&htim5, &sConfigOC, TIM_CHANNEL_1) != HAL_OK)
  {
    Error_Handler();
  }
  if (HAL_TIM_PWM_ConfigChannel(&htim5, &sConfigOC, TIM_CHANNEL_2) != HAL_OK)
  {
    Error_Handler();
  }
  if (HAL_TIM_PWM_ConfigChannel(&htim5, &sConfigOC, TIM_CHANNEL_3) != HAL_OK)
  {
    Error_Handler();
  }
  HAL_TIM_MspPostInit(&htim5);

}

void MX_TIM7_Init(void)
{

  TIM_MasterConfigTypeDef sMasterConfig = {0};

  htim7.Instance = TIM7;
  htim7.Init.Prescaler = 167;
  htim7.Init.CounterMode = TIM_COUNTERMODE_UP;
  htim7.Init.Period = 9;
  htim7.Init.AutoReloadPreload = TIM_AUTORELOAD_PRELOAD_DISABLE;
  if (HAL_TIM_Base_Init(&htim7) != HAL_OK)
  {
    Error_Handler();
  }
  sMasterConfig.MasterOutputTrigger = TIM_TRGO_RESET;
  sMasterConfig.MasterSlaveMode = TIM_MASTERSLAVEMODE_DISABLE;
  if (HAL_TIMEx_MasterConfigSynchronization(&htim7, &sMasterConfig) != HAL_OK)
  {
    Error_Handler();
  }

}

void MX_TIM8_Init(void)
{

  TIM_ClockConfigTypeDef sClockSourceConfig = {0};
  TIM_MasterConfigTypeDef sMasterConfig = {0};
  TIM_OC_InitTypeDef sConfigOC = {0};
  TIM_BreakDeadTimeConfigTypeDef sBreakDeadTimeConfig = {0};

  htim8.Instance = TIM8;
  htim8.Init.Prescaler = 167;
  htim8.Init.CounterMode = TIM_COUNTERMODE_UP;
  htim8.Init.Period = 19999;
  htim8.Init.ClockDivision = TIM_CLOCKDIVISION_DIV1;
  htim8.Init.RepetitionCounter = 0;
  htim8.Init.AutoReloadPreload = TIM_AUTORELOAD_PRELOAD_DISABLE;
  if (HAL_TIM_Base_Init(&htim8) != HAL_OK)
  {
    Error_Handler();
  }
  sClockSourceConfig.ClockSource = TIM_CLOCKSOURCE_INTERNAL;
  if (HAL_TIM_ConfigClockSource(&htim8, &sClockSourceConfig) != HAL_OK)
  {
    Error_Handler();
  }
  if (HAL_TIM_PWM_Init(&htim8) != HAL_OK)
  {
    Error_Handler();
  }
  sMasterConfig.MasterOutputTrigger = TIM_TRGO_RESET;
  sMasterConfig.MasterSlaveMode = TIM_MASTERSLAVEMODE_DISABLE;
  if (HAL_TIMEx_MasterConfigSynchronization(&htim8, &sMasterConfig) != HAL_OK)
  {
    Error_Handler();
  }
  sConfigOC.OCMode = TIM_OCMODE_PWM1;
  sConfigOC.Pulse = 1000;
  sConfigOC.OCPolarity = TIM_OCPOLARITY_HIGH;
  sConfigOC.OCNPolarity = TIM_OCNPOLARITY_HIGH;
  sConfigOC.OCFastMode = TIM_OCFAST_DISABLE;
  sConfigOC.OCIdleState = TIM_OCIDLESTATE_RESET;
  sConfigOC.OCNIdleState = TIM_OCNIDLESTATE_RESET;
  if (HAL_TIM_PWM_ConfigChannel(&htim8, &sConfigOC, TIM_CHANNEL_1) != HAL_OK)
  {
    Error_Handler();
  }
  if (HAL_TIM_PWM_ConfigChannel(&htim8, &sConfigOC, TIM_CHANNEL_2) != HAL_OK)
  {
    Error_Handler();
  }
  sConfigOC.Pulse = 0;
  if (HAL_TIM_PWM_ConfigChannel(&htim8, &sConfigOC, TIM_CHANNEL_3) != HAL_OK)
  {
    Error_Handler();
  }
  sBreakDeadTimeConfig.OffStateRunMode = TIM_OSSR_DISABLE;
  sBreakDeadTimeConfig.OffStateIDLEMode = TIM_OSSI_DISABLE;
  sBreakDeadTimeConfig.LockLevel = TIM_LOCKLEVEL_OFF;
  sBreakDeadTimeConfig.DeadTime = 0;
  sBreakDeadTimeConfig.BreakState = TIM_BREAK_DISABLE;
  sBreakDeadTimeConfig.BreakPolarity = TIM_BREAKPOLARITY_HIGH;
  sBreakDeadTimeConfig.AutomaticOutput = TIM_AUTOMATICOUTPUT_DISABLE;
  if (HAL_TIMEx_ConfigBreakDeadTime(&htim8, &sBreakDeadTimeConfig) != HAL_OK)
  {
    Error_Handler();
  }
  HAL_TIM_MspPostInit(&htim8);

}

void MX_TIM10_Init(void)
{

  TIM_OC_InitTypeDef sConfigOC = {0};

  htim10.Instance = TIM10;
  htim10.Init.Prescaler = 167;
  htim10.Init.CounterMode = TIM_COUNTERMODE_UP;
  htim10.Init.Period = 4999;
  htim10.Init.ClockDivision = TIM_CLOCKDIVISION_DIV1;
  htim10.Init.AutoReloadPreload = TIM_AUTORELOAD_PRELOAD_DISABLE;
  if (HAL_TIM_Base_Init(&htim10) != HAL_OK)
  {
    Error_Handler();
  }
  if (HAL_TIM_PWM_Init(&htim10) != HAL_OK)
  {
    Error_Handler();
  }
  sConfigOC.OCMode = TIM_OCMODE_PWM1;
  sConfigOC.Pulse = 0;
  sConfigOC.OCPolarity = TIM_OCPOLARITY_HIGH;
  sConfigOC.OCFastMode = TIM_OCFAST_DISABLE;
  if (HAL_TIM_PWM_ConfigChannel(&htim10, &sConfigOC, TIM_CHANNEL_1) != HAL_OK)
  {
    Error_Handler();
  }
  HAL_TIM_MspPostInit(&htim10);

}

void MX_USART1_UART_Init(void)
{

  huart1.Instance = USART1;
  huart1.Init.BaudRate = 115200;
  huart1.Init.WordLength = UART_WORDLENGTH_8B;
  huart1.Init.StopBits = UART_STOPBITS_1;
  huart1.Init.Parity = UART_PARITY_NONE;
  huart1.Init.Mode = UART_MODE_TX_RX;
  huart1.Init.HwFlowCtl = UART_HWCONTROL_NONE;
  huart1.Init.OverSampling = UART_OVERSAMPLING_16;
  if (HAL_UART_Init(&huart1) != HAL_OK)
  {
    Error_Handler();
  }

}

void MX_USART3_UART_Init(void)
{

  huart3.Instance = USART3;
  huart3.Init.BaudRate = 100000;
  huart3.Init.WordLength = UART_WORDLENGTH_9B;
  huart3.Init.StopBits = UART_STOPBITS_1;
  huart3.Init.Parity = UART_PARITY_EVEN;
  huart3.Init.Mode = UART_MODE_RX;
  huart3.Init.HwFlowCtl = UART_HWCONTROL_NONE;
  huart3.Init.OverSampling = UART_OVERSAMPLING_16;
  if (HAL_UART_Init(&huart3) != HAL_OK)
  {
    Error_Handler();
  }

}

void MX_USART6_UART_Init(void)
{

  huart6.Instance = USART6;
  huart6.Init.BaudRate = 460800;
  huart6.Init.WordLength = UART_WORDLENGTH_8B;
  huart6.Init.StopBits = UART_STOPBITS_1;
  huart6.Init.Parity = UART_PARITY_NONE;
  huart6.Init.Mode = UART_MODE_TX_RX;
  huart6.Init.HwFlowCtl = UART_HWCONTROL_NONE;
  huart6.Init.OverSampling = UART_OVERSAMPLING_16;
  if (HAL_UART_Init(&huart6) != HAL_OK)
  {
    Error_Handler();
  }

}

static void MX_USB_OTG_FS_PCD_Init(void)
{

  hpcd_USB_OTG_FS.Instance = USB_OTG_FS;
  hpcd_USB_OTG_FS.Init.dev_endpoints = 4;
  hpcd_USB_OTG_FS.Init.speed = PCD_SPEED_FULL;
  hpcd_USB_OTG_FS.Init.dma_enable = DISABLE;
  hpcd_USB_OTG_FS.Init.phy_itface = PCD_PHY_EMBEDDED;
  hpcd_USB_OTG_FS.Init.Sof_enable = DISABLE;
  hpcd_USB_OTG_FS.Init.low_power_enable = DISABLE;
  hpcd_USB_OTG_FS.Init.lpm_enable = DISABLE;
  hpcd_USB_OTG_FS.Init.vbus_sensing_enable = DISABLE;
  hpcd_USB_OTG_FS.Init.use_dedicated_ep1 = DISABLE;
  if (HAL_PCD_Init(&hpcd_USB_OTG_FS) != HAL_OK)
  {
    Error_Handler();
  }

}

void MX_DMA_Init(void)
{

  /* DMA controller clock enable */
  __HAL_RCC_DMA2_CLK_ENABLE();
  __HAL_RCC_DMA1_CLK_ENABLE();

  /* DMA interrupt init */
  /* DMA1_Stream1_IRQn interrupt configuration */
  HAL_NVIC_SetPriority(DMA1_Stream1_IRQn, 5, 0);
  HAL_NVIC_EnableIRQ(DMA1_Stream1_IRQn);
  /* DMA1_Stream2_IRQn interrupt configuration */
  HAL_NVIC_SetPriority(DMA1_Stream2_IRQn, 5, 0);
  HAL_NVIC_EnableIRQ(DMA1_Stream2_IRQn);
  /* DMA1_Stream4_IRQn interrupt configuration */
  HAL_NVIC_SetPriority(DMA1_Stream4_IRQn, 5, 0);
  HAL_NVIC_EnableIRQ(DMA1_Stream4_IRQn);
  /* DMA1_Stream7_IRQn interrupt configuration */
  HAL_NVIC_SetPriority(DMA1_Stream7_IRQn, 5, 0);
  HAL_NVIC_EnableIRQ(DMA1_Stream7_IRQn);
  /* DMA2_Stream0_IRQn interrupt configuration */
  HAL_NVIC_SetPriority(DMA2_Stream0_IRQn, 5, 0);
  HAL_NVIC_EnableIRQ(DMA2_Stream0_IRQn);
  /* DMA2_Stream1_IRQn interrupt configuration */
  HAL_NVIC_SetPriority(DMA2_Stream1_IRQn, 5, 0);
  HAL_NVIC_EnableIRQ(DMA2_Stream1_IRQn);
  /* DMA2_Stream2_IRQn interrupt configuration */
  HAL_NVIC_SetPriority(DMA2_Stream2_IRQn, 5, 0);
  HAL_NVIC_EnableIRQ(DMA2_Stream2_IRQn);
  /* DMA2_Stream3_IRQn interrupt configuration */
  HAL_NVIC_SetPriority(DMA2_Stream3_IRQn, 5, 0);
  HAL_NVIC_EnableIRQ(DMA2_Stream3_IRQn);
  /* DMA2_Stream4_IRQn interrupt configuration */
  HAL_NVIC_SetPriority(DMA2_Stream4_IRQn, 5, 0);
  HAL_NVIC_EnableIRQ(DMA2_Stream4_IRQn);
  /* DMA2_Stream5_IRQn interrupt configuration */
  HAL_NVIC_SetPriority(DMA2_Stream5_IRQn, 5, 0);
  HAL_NVIC_EnableIRQ(DMA2_Stream5_IRQn);
  /* DMA2_Stream6_IRQn interrupt configuration */
  HAL_NVIC_SetPriority(DMA2_Stream6_IRQn, 5, 0);
  HAL_NVIC_EnableIRQ(DMA2_Stream6_IRQn);
  /* DMA2_Stream7_IRQn interrupt configuration */
  HAL_NVIC_SetPriority(DMA2_Stream7_IRQn, 5, 0);
  HAL_NVIC_EnableIRQ(DMA2_Stream7_IRQn);

}

void MX_GPIO_Init(void)
{
  GPIO_InitTypeDef GPIO_InitStruct = {0};

  /* GPIO Ports Clock Enable */
  __HAL_RCC_GPIOB_CLK_ENABLE();
  __HAL_RCC_GPIOG_CLK_ENABLE();
  __HAL_RCC_GPIOA_CLK_ENABLE();
  __HAL_RCC_GPIOD_CLK_ENABLE();
  __HAL_RCC_GPIOC_CLK_ENABLE();
  __HAL_RCC_GPIOI_CLK_ENABLE();
  __HAL_RCC_GPIOF_CLK_ENABLE();
  __HAL_RCC_GPIOH_CLK_ENABLE();
  __HAL_RCC_GPIOE_CLK_ENABLE();

  /*Configure GPIO pin Output Level */
  HAL_GPIO_WritePin(CMPS_RST_GPIO_Port, CMPS_RST_Pin, GPIO_PIN_RESET);

  /*Configure GPIO pin Output Level */
  HAL_GPIO_WritePin(ACCL_CS_GPIO_Port, ACCL_CS_Pin, GPIO_PIN_SET);

  /*Configure GPIO pin Output Level */
  HAL_GPIO_WritePin(GYRO_CS_GPIO_Port, GYRO_CS_Pin, GPIO_PIN_SET);

  /*Configure GPIO pin : CMPS_RST_Pin */
  GPIO_InitStruct.Pin = CMPS_RST_Pin;
  GPIO_InitStruct.Mode = GPIO_MODE_OUTPUT_PP;
  GPIO_InitStruct.Pull = GPIO_PULLUP;
  GPIO_InitStruct.Speed = GPIO_SPEED_FREQ_MEDIUM;
  HAL_GPIO_Init(CMPS_RST_GPIO_Port, &GPIO_InitStruct);

  /*Configure GPIO pin : CMPS_INT_Pin */
  GPIO_InitStruct.Pin = CMPS_INT_Pin;
  GPIO_InitStruct.Mode = GPIO_MODE_IT_FALLING;
  GPIO_InitStruct.Pull = GPIO_PULLUP;
  HAL_GPIO_Init(CMPS_INT_GPIO_Port, &GPIO_InitStruct);

  /*Configure GPIO pins : HW0_Pin HW1_Pin HW2_Pin */
  GPIO_InitStruct.Pin = HW0_Pin|HW1_Pin|HW2_Pin;
  GPIO_InitStruct.Mode = GPIO_MODE_INPUT;
  GPIO_InitStruct.Pull = GPIO_NOPULL;
  HAL_GPIO_Init(GPIOC, &GPIO_InitStruct);

  /*Configure GPIO pin : USER_KEY_Pin */
  GPIO_InitStruct.Pin = USER_KEY_Pin;
  GPIO_InitStruct.Mode = GPIO_MODE_IT_FALLING;
  GPIO_InitStruct.Pull = GPIO_PULLUP;
  HAL_GPIO_Init(USER_KEY_GPIO_Port, &GPIO_InitStruct);

  /*Configure GPIO pin : ACCL_CS_Pin */
  GPIO_InitStruct.Pin = ACCL_CS_Pin;
  GPIO_InitStruct.Mode = GPIO_MODE_OUTPUT_PP;
  GPIO_InitStruct.Pull = GPIO_PULLUP;
  GPIO_InitStruct.Speed = GPIO_SPEED_FREQ_MEDIUM;
  HAL_GPIO_Init(ACCL_CS_GPIO_Port, &GPIO_InitStruct);

  /*Configure GPIO pins : ACCL_INT_Pin GYRO_INT_Pin */
  GPIO_InitStruct.Pin = ACCL_INT_Pin|GYRO_INT_Pin;
  GPIO_InitStruct.Mode = GPIO_MODE_IT_FALLING;
  GPIO_InitStruct.Pull = GPIO_PULLUP;
  HAL_GPIO_Init(GPIOC, &GPIO_InitStruct);

  /*Configure GPIO pin : GYRO_CS_Pin */
  GPIO_InitStruct.Pin = GYRO_CS_Pin;
  GPIO_InitStruct.Mode = GPIO_MODE_OUTPUT_PP;
  GPIO_InitStruct.Pull = GPIO_PULLUP;
  GPIO_InitStruct.Speed = GPIO_SPEED_FREQ_MEDIUM;
  HAL_GPIO_Init(GYRO_CS_GPIO_Port, &GPIO_InitStruct);

  /*Configure GPIO pins : PB14 PB15 */
  GPIO_InitStruct.Pin = GPIO_PIN_14|GPIO_PIN_15;
  GPIO_InitStruct.Mode = GPIO_MODE_AF_PP;
  GPIO_InitStruct.Pull = GPIO_PULLUP;
  GPIO_InitStruct.Speed = GPIO_SPEED_FREQ_VERY_HIGH;
  GPIO_InitStruct.Alternate = GPIO_AF5_SPI2;
  HAL_GPIO_Init(GPIOB, &GPIO_InitStruct);

  /* EXTI interrupt init*/
  HAL_NVIC_SetPriority(EXTI0_IRQn, 5, 0);
  HAL_NVIC_EnableIRQ(EXTI0_IRQn);

  HAL_NVIC_SetPriority(EXTI3_IRQn, 5, 0);
  HAL_NVIC_EnableIRQ(EXTI3_IRQn);

  HAL_NVIC_SetPriority(EXTI4_IRQn, 5, 0);
  HAL_NVIC_EnableIRQ(EXTI4_IRQn);

  HAL_NVIC_SetPriority(EXTI9_5_IRQn, 5, 0);
  HAL_NVIC_EnableIRQ(EXTI9_5_IRQn);

}

/* USER CODE BEGIN 4 */
#include "app_main.h"
/* USER CODE END 4 */

void StartDefaultTask(void const * argument)
{
  /* USER CODE BEGIN 5 */
  app_main();
  /* Infinite loop */
  for(;;)
  {
    osDelay(1);
  }
  /* USER CODE END 5 */
}

void HAL_TIM_PeriodElapsedCallback(TIM_HandleTypeDef *htim)
{
  if (htim->Instance == TIM2)
  {
    HAL_IncTick();
  }
}

void Error_Handler(void)
{
  __disable_irq();
  while (1)
  {
  }
}

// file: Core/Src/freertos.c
/* USER CODE BEGIN Header */
/**
  ******************************************************************************
  * File Name          : freertos.c
  * Description        : Code for freertos applications
  ******************************************************************************
  * @attention
  *
  * Copyright (c) 2025 STMicroelectronics.
  * All rights reserved.
  *
  * This software is licensed under terms that can be found in the LICENSE file
  * in the root directory of this software component.
  * If no LICENSE file comes with this software, it is provided AS-IS.
  *
  ******************************************************************************
  */
/* USER CODE END Header */

#include "FreeRTOS.h"
#include "task.h"
#include "main.h"

/* Hook prototypes */
void configureTimerForRunTimeStats(void);
unsigned long getRunTimeCounterValue(void);

/* USER CODE BEGIN 1 */
/* Functions needed when configGENERATE_RUN_TIME_STATS is on */
__weak void configureTimerForRunTimeStats(void)
{

}

__weak unsigned long getRunTimeCounterValue(void)
{
return 0;
}
/* USER CODE END 1 */
